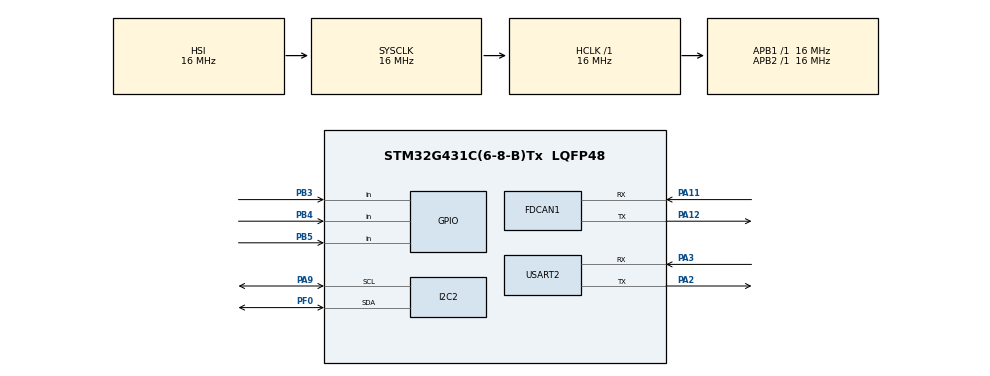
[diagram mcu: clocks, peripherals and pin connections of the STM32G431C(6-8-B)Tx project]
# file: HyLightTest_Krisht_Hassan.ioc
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FDCAN1.CalculateBaudRateNominal=333333
FDCAN1.CalculateTimeBitNominal=3000
FDCAN1.CalculateTimeQuantumNominal=1000.0
I2C2.Timing=0x00503D58
Mcu.Family=STM32G4
Mcu.Name=STM32G431C(6-8-B)Tx
Mcu.Package=LQFP48
NVIC.PriorityGroup=NVIC_PRIORITYGROUP_4
NVIC.USART2_IRQn=true\:0\:0\:false\:false\:true\:true\:true\:true
PA11.Mode=FDCAN_Activate
PA11.Signal=FDCAN1_RX
PA12.Mode=FDCAN_Activate
PA12.Signal=FDCAN1_TX
PA2.Mode=Asynchronous
PA2.Signal=USART2_TX
PA3.Mode=Asynchronous
PA3.Signal=USART2_RX
PA9.Mode=I2C
PA9.Signal=I2C2_SCL
PB3.Signal=GPIO_Input
PB4.Signal=GPIO_Input
PB5.Signal=GPIO_Input
PF0-OSC_IN.Mode=I2C
PF0-OSC_IN.Signal=I2C2_SDA
ProjectManager.HeapSize=0x200
ProjectManager.StackSize=0x400
ProjectManager.TargetToolchain=CMake
RCC.AHBFreq_Value=16000000
RCC.APB1Freq_Value=16000000
RCC.APB1TimFreq_Value=16000000
RCC.APB2Freq_Value=16000000
RCC.APB2TimFreq_Value=16000000
RCC.CortexFreq_Value=16000000
RCC.EXTERNAL_CLOCK_VALUE=12288000
RCC.HCLKFreq_Value=16000000
RCC.HSE_VALUE=8000000
RCC.HSI48_VALUE=48000000
RCC.HSI_VALUE=16000000
RCC.LSE_VALUE=32768
RCC.SYSCLKFreq_VALUE=16000000
RCC.USBFreq_Value=64000000
RCC.VCOOutputFreq_Value=128000000
USART2.VirtualMode-Asynchronous=VM_ASYNC
VP_CRC_VS_CRC.Mode=CRC_Activate
VP_SYS_VS_DBSignals.Mode=DisableDeadBatterySignals
board=custom

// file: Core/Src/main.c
/* USER CODE BEGIN Header */
/**
  ******************************************************************************
  * @file           : main.c
  * @brief          : Main program body
  ******************************************************************************
  * @attention
  *
  * Copyright (c) 2026 STMicroelectronics.
  * All rights reserved.
  *
  * This software is licensed under terms that can be found in the LICENSE file
  * in the root directory of this software component.
  * If no LICENSE file comes with this software, it is provided AS-IS.
  *
  ******************************************************************************
  */
/* USER CODE END Header */
#include "main.h"

/* USER CODE BEGIN Includes */
#include "app.h"

/* USER CODE END Includes */

CRC_HandleTypeDef hcrc;

FDCAN_HandleTypeDef hfdcan1;

I2C_HandleTypeDef hi2c2;

UART_HandleTypeDef huart2;

void SystemClock_Config(void);
static void MX_GPIO_Init(void);
static void MX_FDCAN1_Init(void);
static void MX_USART2_UART_Init(void);
static void MX_CRC_Init(void);
static void MX_I2C2_Init(void);

int main(void)
{

  /* MCU Configuration--------------------------------------------------------*/

  /* Reset of all peripherals, Initializes the Flash interface and the Systick. */
  HAL_Init();

  /* Configure the system clock */
  SystemClock_Config();

  /* Initialize all configured peripherals */
  MX_GPIO_Init();
  MX_FDCAN1_Init();
  MX_USART2_UART_Init();
  MX_CRC_Init();
  MX_I2C2_Init();
  /* USER CODE BEGIN 2 */
  /* initialize application layer (drivers & services) */
  app_init();

  /* USER CODE END 2 */

  /* Infinite loop */
  while (1)
  {

    /* USER CODE BEGIN 3 */
    static uint32_t last_poll = 0;
    if (HAL_GetTick() - last_poll >= 50) {
      last_poll = HAL_GetTick();
      app_poll();
    }
  }
  /* USER CODE END 3 */
}

void SystemClock_Config(void)
{
  RCC_OscInitTypeDef RCC_OscInitStruct = {0};
  RCC_ClkInitTypeDef RCC_ClkInitStruct = {0};

  /** Configure the main internal regulator output voltage
  */
  HAL_PWREx_ControlVoltageScaling(PWR_REGULATOR_VOLTAGE_SCALE1);

  /** Initializes the RCC Oscillators according to the specified parameters
  * in the RCC_OscInitTypeDef structure.
  */
  RCC_OscInitStruct.OscillatorType = RCC_OSCILLATORTYPE_HSI;
  RCC_OscInitStruct.HSIState = RCC_HSI_ON;
  RCC_OscInitStruct.HSICalibrationValue = RCC_HSICALIBRATION_DEFAULT;
  RCC_OscInitStruct.PLL.PLLState = RCC_PLL_NONE;
  if (HAL_RCC_OscConfig(&RCC_OscInitStruct) != HAL_OK)
  {
    Error_Handler();
  }

  /** Initializes the CPU, AHB and APB buses clocks
  */
  RCC_ClkInitStruct.ClockType = RCC_CLOCKTYPE_HCLK|RCC_CLOCKTYPE_SYSCLK
                              |RCC_CLOCKTYPE_PCLK1|RCC_CLOCKTYPE_PCLK2;
  RCC_ClkInitStruct.SYSCLKSource = RCC_SYSCLKSOURCE_HSI;
  RCC_ClkInitStruct.AHBCLKDivider = RCC_SYSCLK_DIV1;
  RCC_ClkInitStruct.APB1CLKDivider = RCC_HCLK_DIV1;
  RCC_ClkInitStruct.APB2CLKDivider = RCC_HCLK_DIV1;

  if (HAL_RCC_ClockConfig(&RCC_ClkInitStruct, FLASH_LATENCY_0) != HAL_OK)
  {
    Error_Handler();
  }
}

static void MX_CRC_Init(void)
{

  hcrc.Instance = CRC;
  hcrc.Init.DefaultPolynomialUse = DEFAULT_POLYNOMIAL_ENABLE;
  hcrc.Init.DefaultInitValueUse = DEFAULT_INIT_VALUE_ENABLE;
  hcrc.Init.InputDataInversionMode = CRC_INPUTDATA_INVERSION_NONE;
  hcrc.Init.OutputDataInversionMode = CRC_OUTPUTDATA_INVERSION_DISABLE;
  hcrc.InputDataFormat = CRC_INPUTDATA_FORMAT_BYTES;
  if (HAL_CRC_Init(&hcrc) != HAL_OK)
  {
    Error_Handler();
  }

}

static void MX_FDCAN1_Init(void)
{

  hfdcan1.Instance = FDCAN1;
  hfdcan1.Init.ClockDivider = FDCAN_CLOCK_DIV1;
  hfdcan1.Init.FrameFormat = FDCAN_FRAME_CLASSIC;
  hfdcan1.Init.Mode = FDCAN_MODE_NORMAL;
  hfdcan1.Init.AutoRetransmission = DISABLE;
  hfdcan1.Init.TransmitPause = DISABLE;
  hfdcan1.Init.ProtocolException = DISABLE;
  hfdcan1.Init.NominalPrescaler = 16;
  hfdcan1.Init.NominalSyncJumpWidth = 1;
  hfdcan1.Init.NominalTimeSeg1 = 1;
  hfdcan1.Init.NominalTimeSeg2 = 1;
  hfdcan1.Init.DataPrescaler = 1;
  hfdcan1.Init.DataSyncJumpWidth = 1;
  hfdcan1.Init.DataTimeSeg1 = 1;
  hfdcan1.Init.DataTimeSeg2 = 1;
  hfdcan1.Init.StdFiltersNbr = 0;
  hfdcan1.Init.ExtFiltersNbr = 0;
  hfdcan1.Init.TxFifoQueueMode = FDCAN_TX_FIFO_OPERATION;
  if (HAL_FDCAN_Init(&hfdcan1) != HAL_OK)
  {
    Error_Handler();
  }
  /* Start FDCAN controller so TX is possible */
  if (HAL_FDCAN_Start(&hfdcan1) != HAL_OK)
  {
    Error_Handler();
  }

}

static void MX_I2C2_Init(void)
{

  hi2c2.Instance = I2C2;
  hi2c2.Init.Timing = 0x00503D58;
  hi2c2.Init.OwnAddress1 = 0;
  hi2c2.Init.AddressingMode = I2C_ADDRESSINGMODE_7BIT;
  hi2c2.Init.DualAddressMode = I2C_DUALADDRESS_DISABLE;
  hi2c2.Init.OwnAddress2 = 0;
  hi2c2.Init.OwnAddress2Masks = I2C_OA2_NOMASK;
  hi2c2.Init.GeneralCallMode = I2C_GENERALCALL_DISABLE;
  hi2c2.Init.NoStretchMode = I2C_NOSTRETCH_DISABLE;
  if (HAL_I2C_Init(&hi2c2) != HAL_OK)
  {
    Error_Handler();
  }

  /** Configure Analogue filter
  */
  if (HAL_I2CEx_ConfigAnalogFilter(&hi2c2, I2C_ANALOGFILTER_ENABLE) != HAL_OK)
  {
    Error_Handler();
  }

  /** Configure Digital filter
  */
  if (HAL_I2CEx_ConfigDigitalFilter(&hi2c2, 0) != HAL_OK)
  {
    Error_Handler();
  }

}

static void MX_USART2_UART_Init(void)
{

  huart2.Instance = USART2;
  huart2.Init.BaudRate = 115200;
  huart2.Init.WordLength = UART_WORDLENGTH_8B;
  huart2.Init.StopBits = UART_STOPBITS_1;
  huart2.Init.Parity = UART_PARITY_NONE;
  huart2.Init.Mode = UART_MODE_TX_RX;
  huart2.Init.HwFlowCtl = UART_HWCONTROL_NONE;
  huart2.Init.OverSampling = UART_OVERSAMPLING_16;
  huart2.Init.OneBitSampling = UART_ONE_BIT_SAMPLE_DISABLE;
  huart2.Init.ClockPrescaler = UART_PRESCALER_DIV1;
  huart2.AdvancedInit.AdvFeatureInit = UART_ADVFEATURE_NO_INIT;
  if (HAL_UART_Init(&huart2) != HAL_OK)
  {
    Error_Handler();
  }
  if (HAL_UARTEx_SetTxFifoThreshold(&huart2, UART_TXFIFO_THRESHOLD_1_8) != HAL_OK)
  {
    Error_Handler();
  }
  if (HAL_UARTEx_SetRxFifoThreshold(&huart2, UART_RXFIFO_THRESHOLD_1_8) != HAL_OK)
  {
    Error_Handler();
  }
  if (HAL_UARTEx_DisableFifoMode(&huart2) != HAL_OK)
  {
    Error_Handler();
  }

}

static void MX_GPIO_Init(void)
{
  GPIO_InitTypeDef GPIO_InitStruct = {0};

  /* GPIO Ports Clock Enable */
  __HAL_RCC_GPIOF_CLK_ENABLE();
  __HAL_RCC_GPIOA_CLK_ENABLE();
  __HAL_RCC_GPIOB_CLK_ENABLE();

  /*Configure GPIO pins : PB3 PB4 PB5 */
  GPIO_InitStruct.Pin = GPIO_PIN_3|GPIO_PIN_4|GPIO_PIN_5;
  GPIO_InitStruct.Mode = GPIO_MODE_INPUT;
  GPIO_InitStruct.Pull = GPIO_NOPULL;
  HAL_GPIO_Init(GPIOB, &GPIO_InitStruct);

}

void Error_Handler(void)
{
  __disable_irq();
  while (1)
  {
  }
}
